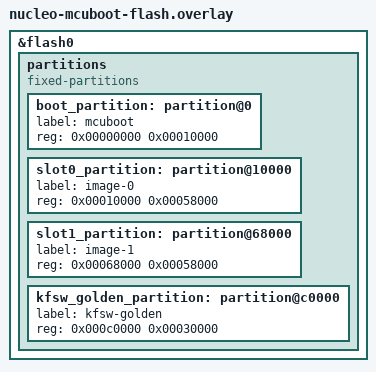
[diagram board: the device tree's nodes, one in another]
/* MCUboot flash map for the NUCLEO-L496ZG, applied to both the bootloader and
 * the application so they agree on the slots.
 *
 * The storage partition at 0xf0000 is not listed here; it stays where it is so
 * the filesystem survives the move to MCUboot. The golden region is reserved
 * for a recovery image.
 *
 * Every boundary is a multiple of the 2 KB erase block.
 */

&flash0 {
	partitions {
		compatible = "fixed-partitions";
		#address-cells = <1>;
		#size-cells = <1>;

		boot_partition: partition@0 {
			label = "mcuboot";
			reg = <0x00000000 0x00010000>;
		};

		slot0_partition: partition@10000 {
			label = "image-0";
			reg = <0x00010000 0x00058000>;
		};

		slot1_partition: partition@68000 {
			label = "image-1";
			reg = <0x00068000 0x00058000>;
		};

		kfsw_golden_partition: partition@c0000 {
			label = "kfsw-golden";
			reg = <0x000c0000 0x00030000>;
		};
	};
};
